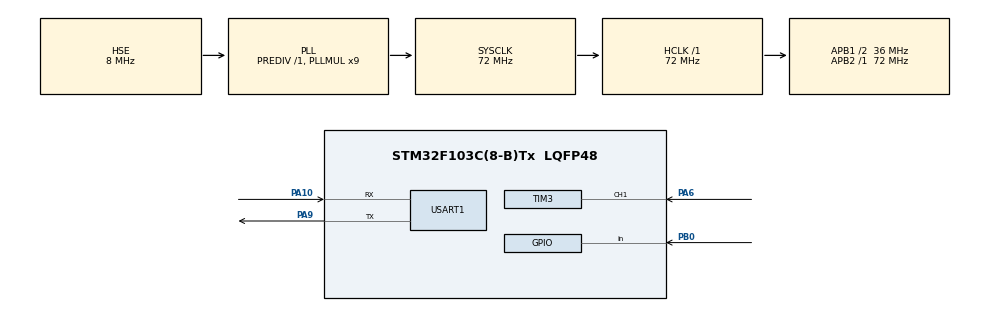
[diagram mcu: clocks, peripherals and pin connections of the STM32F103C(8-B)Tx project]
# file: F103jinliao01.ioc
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Mcu.Family=STM32F1
Mcu.Name=STM32F103C(8-B)Tx
Mcu.Package=LQFP48
NVIC.PriorityGroup=NVIC_PRIORITYGROUP_4
NVIC.USART1_IRQn=true\:0\:0\:false\:false\:true\:true\:true\:true
PA10.Mode=Asynchronous
PA10.Signal=USART1_RX
PA13.Mode=Serial_Wire
PA13.Signal=SYS_JTMS-SWDIO
PA14.Mode=Serial_Wire
PA14.Signal=SYS_JTCK-SWCLK
PA6.GPIO_PuPd=GPIO_PULLUP
PA6.Signal=S_TIM3_CH1
PA9.Mode=Asynchronous
PA9.Signal=USART1_TX
PB0.GPIO_PuPd=GPIO_PULLUP
PB0.Signal=GPIO_Input
PD0-OSC_IN.Mode=HSE-External-Oscillator
PD0-OSC_IN.Signal=RCC_OSC_IN
PD1-OSC_OUT.Mode=HSE-External-Oscillator
PD1-OSC_OUT.Signal=RCC_OSC_OUT
ProjectManager.HeapSize=0x200
ProjectManager.StackSize=0x400
ProjectManager.TargetToolchain=MDK-ARM V5.32
RCC.AHBFreq_Value=72000000
RCC.APB1CLKDivider=RCC_HCLK_DIV2
RCC.APB1Freq_Value=36000000
RCC.APB1TimFreq_Value=72000000
RCC.APB2Freq_Value=72000000
RCC.APB2TimFreq_Value=72000000
RCC.HCLKFreq_Value=72000000
RCC.PLLMUL=RCC_PLL_MUL9
RCC.PLLSourceVirtual=RCC_PLLSOURCE_HSE
RCC.SYSCLKFreq_VALUE=72000000
RCC.SYSCLKSource=RCC_SYSCLKSOURCE_PLLCLK
RCC.USBFreq_Value=72000000
SH.S_TIM3_CH1.0=TIM3_CH1,Input_Capture1_from_TI1
TIM3.Channel-Input_Capture1_from_TI1=TIM_CHANNEL_1
TIM3.ICFilter_CH1=15
TIM3.ICPolarity_CH1=TIM_INPUTCHANNELPOLARITY_FALLING
TIM3.Prescaler=71
USART1.VirtualMode=VM_ASYNC
VP_TIM3_VS_ClockSourceINT.Mode=Internal
board=custom

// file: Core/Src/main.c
/* USER CODE BEGIN Header */
/**
 ******************************************************************************
 * @file           : main.c
 * @brief          : Main program body
 ******************************************************************************
 * @attention
 *
 * Copyright (c) 2026 STMicroelectronics.
 * All rights reserved.
 *
 * This software is licensed under terms that can be found in the LICENSE file
 * in the root directory of this software component.
 * If no LICENSE file comes with this software, it is provided AS-IS.
 *
 ******************************************************************************
 */
/* USER CODE END Header */

#include "main.h"

/* USER CODE BEGIN Includes */
#include "sensor.h"
#include "usart_protocol.h"
#include "timing.h"
/* USER CODE END Includes */

TIM_HandleTypeDef htim3;

UART_HandleTypeDef huart1;

/* USER CODE BEGIN PV */

void SystemClock_Config(void);
static void MX_GPIO_Init(void);
static void MX_USART1_UART_Init(void);
static void MX_TIM3_Init(void);

int main(void)
{

    /* MCU Configuration--------------------------------------------------------*/

    /* Reset of all peripherals, Initializes the Flash interface and the Systick. */
    HAL_Init();

    /* Configure the system clock */
    SystemClock_Config();

    /* Initialize all configured peripherals */
    MX_GPIO_Init();
    MX_USART1_UART_Init();
    MX_TIM3_Init();

    /* USER CODE BEGIN 2 */

    /* 传感器模块初始化 */
    Sensor_Init();

    /* 启动霍尔传感器TIM3输入捕获 */
    Hall_Start();

    /* 协议模块初始化 */
    Protocol_Init();

    /* 发送管理初始化 */
    Timing_Init();

    /* USER CODE END 2 */

    /* Infinite loop */
    while (1)
    {

        /* USER CODE BEGIN 3 */

        /* 更新所有传感器数据 */
        Sensor_Update();

        /* 组帧并发送 (等待上一帧发完) */
        if (g_tx_ready == 1) {
            Protocol_SendFrame();
        }

        /* 50ms周期 */
        HAL_Delay(50);

        /* USER CODE END 3 */
    }
}

void SystemClock_Config(void)
{
    RCC_OscInitTypeDef RCC_OscInitStruct = {0};
    RCC_ClkInitTypeDef RCC_ClkInitStruct = {0};

    /** Initializes the RCC Oscillators according to the specified parameters
    * in the RCC_OscInitTypeDef structure.
    */
    RCC_OscInitStruct.OscillatorType = RCC_OSCILLATORTYPE_HSE;
    RCC_OscInitStruct.HSEState = RCC_HSE_ON;
    RCC_OscInitStruct.HSEPredivValue = RCC_HSE_PREDIV_DIV1;
    RCC_OscInitStruct.HSIState = RCC_HSI_ON;
    RCC_OscInitStruct.PLL.PLLState = RCC_PLL_ON;
    RCC_OscInitStruct.PLL.PLLSource = RCC_PLLSOURCE_HSE;
    RCC_OscInitStruct.PLL.PLLMUL = RCC_PLL_MUL9;
    if (HAL_RCC_OscConfig(&RCC_OscInitStruct) != HAL_OK)
    {
        Error_Handler();
    }

    /** Initializes the CPU, AHB and APB buses clocks
    */
    RCC_ClkInitStruct.ClockType = RCC_CLOCKTYPE_HCLK|RCC_CLOCKTYPE_SYSCLK
                                |RCC_CLOCKTYPE_PCLK1|RCC_CLOCKTYPE_PCLK2;
    RCC_ClkInitStruct.SYSCLKSource = RCC_SYSCLKSOURCE_PLLCLK;
    RCC_ClkInitStruct.AHBCLKDivider = RCC_SYSCLK_DIV1;
    RCC_ClkInitStruct.APB1CLKDivider = RCC_HCLK_DIV2;
    RCC_ClkInitStruct.APB2CLKDivider = RCC_HCLK_DIV1;

    if (HAL_RCC_ClockConfig(&RCC_ClkInitStruct, FLASH_LATENCY_2) != HAL_OK)
    {
        Error_Handler();
    }
}

static void MX_TIM3_Init(void)
{

    TIM_ClockConfigTypeDef sClockSourceConfig = {0};
    TIM_MasterConfigTypeDef sMasterConfig = {0};
    TIM_IC_InitTypeDef sConfigIC = {0};

    htim3.Instance = TIM3;
    htim3.Init.Prescaler = 71;
    htim3.Init.CounterMode = TIM_COUNTERMODE_UP;
    htim3.Init.Period = 65535;
    htim3.Init.ClockDivision = TIM_CLOCKDIVISION_DIV1;
    htim3.Init.AutoReloadPreload = TIM_AUTORELOAD_PRELOAD_DISABLE;
    if (HAL_TIM_Base_Init(&htim3) != HAL_OK)
    {
        Error_Handler();
    }
    sClockSourceConfig.ClockSource = TIM_CLOCKSOURCE_INTERNAL;
    if (HAL_TIM_ConfigClockSource(&htim3, &sClockSourceConfig) != HAL_OK)
    {
        Error_Handler();
    }
    if (HAL_TIM_IC_Init(&htim3) != HAL_OK)
    {
        Error_Handler();
    }
    sMasterConfig.MasterOutputTrigger = TIM_TRGO_RESET;
    sMasterConfig.MasterSlaveMode = TIM_MASTERSLAVEMODE_DISABLE;
    if (HAL_TIMEx_MasterConfigSynchronization(&htim3, &sMasterConfig) != HAL_OK)
    {
        Error_Handler();
    }
    sConfigIC.ICPolarity = TIM_INPUTCHANNELPOLARITY_FALLING;
    sConfigIC.ICSelection = TIM_ICSELECTION_DIRECTTI;
    sConfigIC.ICPrescaler = TIM_ICPSC_DIV1;
    sConfigIC.ICFilter = 8;
    if (HAL_TIM_IC_ConfigChannel(&htim3, &sConfigIC, TIM_CHANNEL_1) != HAL_OK)
    {
        Error_Handler();
    }

}

static void MX_USART1_UART_Init(void)
{

    huart1.Instance = USART1;
    huart1.Init.BaudRate = 115200;
    huart1.Init.WordLength = UART_WORDLENGTH_8B;
    huart1.Init.StopBits = UART_STOPBITS_1;
    huart1.Init.Parity = UART_PARITY_NONE;
    huart1.Init.Mode = UART_MODE_TX_RX;
    huart1.Init.HwFlowCtl = UART_HWCONTROL_NONE;
    huart1.Init.OverSampling = UART_OVERSAMPLING_16;
    if (HAL_UART_Init(&huart1) != HAL_OK)
    {
        Error_Handler();
    }

}

static void MX_GPIO_Init(void)
{
    GPIO_InitTypeDef GPIO_InitStruct = {0};

    /* GPIO Ports Clock Enable */
    __HAL_RCC_GPIOD_CLK_ENABLE();
    __HAL_RCC_GPIOA_CLK_ENABLE();
    __HAL_RCC_GPIOB_CLK_ENABLE();

    /*Configure GPIO pin : PB0 */
    GPIO_InitStruct.Pin = GPIO_PIN_0;
    GPIO_InitStruct.Mode = GPIO_MODE_INPUT;
    GPIO_InitStruct.Pull = GPIO_PULLUP;
    HAL_GPIO_Init(GPIOB, &GPIO_InitStruct);

}

/* USER CODE BEGIN 4 */

/*========================== UART 回调 ==========================*/

/**
 * @brief  UART发送完成回调 (HAL库自动调用)
 */
void HAL_UART_TxCpltCallback(UART_HandleTypeDef *huart)
{
    if (huart->Instance == USART1) {
        Protocol_TxCpltCallback();
    }
}

/* USER CODE END 4 */

void Error_Handler(void)
{
    __disable_irq();
    while (1)
    {
    }
}
